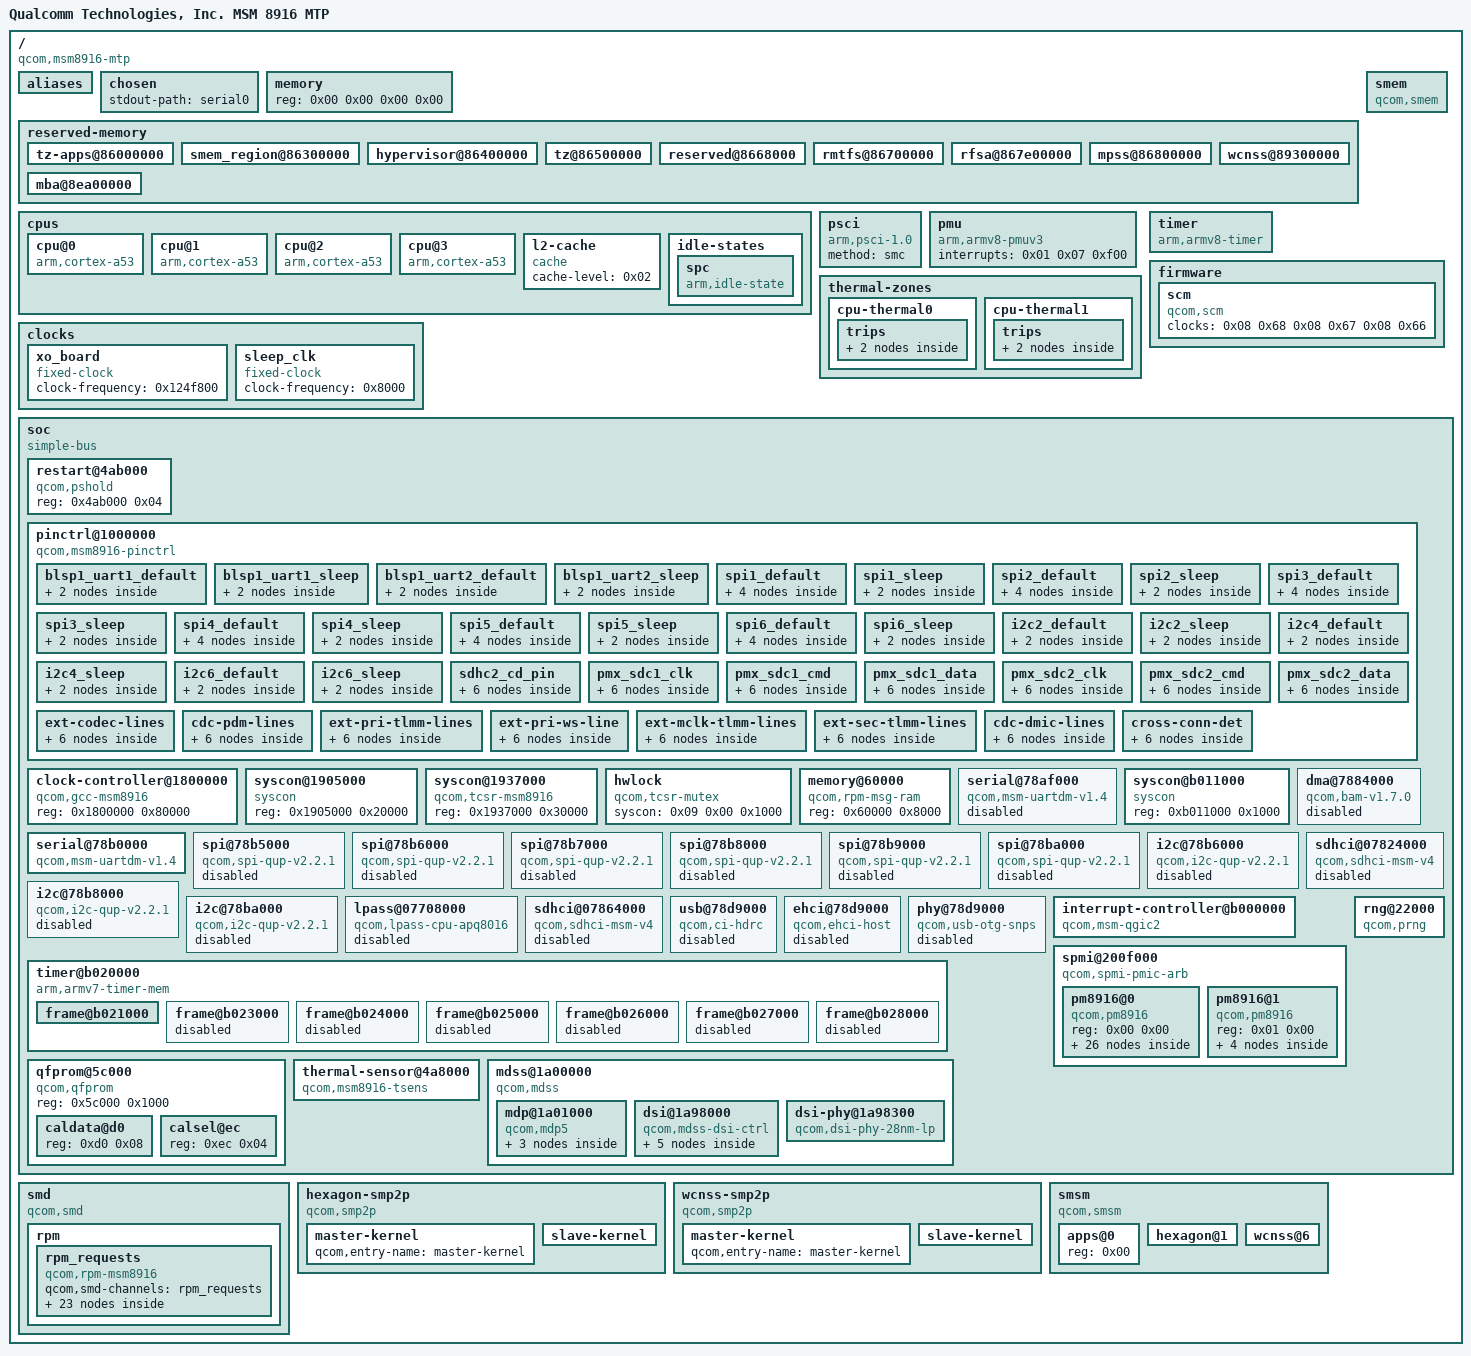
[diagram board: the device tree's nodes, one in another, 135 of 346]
/dts-v1/;

/ {
	model = "Qualcomm Technologies, Inc. MSM 8916 MTP";
	compatible = "qcom,msm8916-mtp\0qcom,msm8916-mtp/1\0qcom,msm8916\0qcom,mtp";
	interrupt-parent = <0x01>;
	#address-cells = <0x02>;
	#size-cells = <0x02>;

	aliases {
		sdhc1 = "/soc/sdhci@07824000";
		sdhc2 = "/soc/sdhci@07864000";
		serial0 = "/soc/serial@78b0000";
		usid0 = "/soc/spmi@200f000/pm8916@0";
	};

	chosen {
		stdout-path = "serial0";
	};

	memory {
		device_type = "memory";
		reg = <0x00 0x00 0x00 0x00>;
	};

	reserved-memory {
		#address-cells = <0x02>;
		#size-cells = <0x02>;
		ranges;

		tz-apps@86000000 {
			reg = <0x00 0x86000000 0x00 0x300000>;
			no-map;
		};

		smem_region@86300000 {
			reg = <0x00 0x86300000 0x00 0x100000>;
			no-map;
			phandle = <0x05>;
		};

		hypervisor@86400000 {
			reg = <0x00 0x86400000 0x00 0x100000>;
			no-map;
		};

		tz@86500000 {
			reg = <0x00 0x86500000 0x00 0x180000>;
			no-map;
		};

		reserved@8668000 {
			reg = <0x00 0x86680000 0x00 0x80000>;
			no-map;
		};

		rmtfs@86700000 {
			reg = <0x00 0x86700000 0x00 0xe0000>;
			no-map;
		};

		rfsa@867e00000 {
			reg = <0x00 0x867e0000 0x00 0x20000>;
			no-map;
		};

		mpss@86800000 {
			reg = <0x00 0x86800000 0x00 0x2b00000>;
			no-map;
		};

		wcnss@89300000 {
			reg = <0x00 0x89300000 0x00 0x600000>;
			no-map;
		};

		mba@8ea00000 {
			no-map;
			reg = <0x00 0x8ea00000 0x00 0x100000>;
			phandle = <0x2e>;
		};
	};

	cpus {
		#address-cells = <0x01>;
		#size-cells = <0x00>;

		cpu@0 {
			device_type = "cpu";
			compatible = "arm,cortex-a53\0arm,armv8";
			reg = <0x00>;
			next-level-cache = <0x02>;
			enable-method = "psci";
			cpu-idle-states = <0x03>;
			phandle = <0x2f>;
		};

		cpu@1 {
			device_type = "cpu";
			compatible = "arm,cortex-a53\0arm,armv8";
			reg = <0x01>;
			next-level-cache = <0x02>;
			enable-method = "psci";
			cpu-idle-states = <0x03>;
			phandle = <0x30>;
		};

		cpu@2 {
			device_type = "cpu";
			compatible = "arm,cortex-a53\0arm,armv8";
			reg = <0x02>;
			next-level-cache = <0x02>;
			enable-method = "psci";
			cpu-idle-states = <0x03>;
			phandle = <0x31>;
		};

		cpu@3 {
			device_type = "cpu";
			compatible = "arm,cortex-a53\0arm,armv8";
			reg = <0x03>;
			next-level-cache = <0x02>;
			enable-method = "psci";
			cpu-idle-states = <0x03>;
			phandle = <0x32>;
		};

		l2-cache {
			compatible = "cache";
			cache-level = <0x02>;
			phandle = <0x02>;
		};

		idle-states {

			spc {
				compatible = "arm,idle-state";
				arm,psci-suspend-param = <0x40000002>;
				entry-latency-us = <0x82>;
				exit-latency-us = <0x96>;
				min-residency-us = <0x7d0>;
				local-timer-stop;
				phandle = <0x03>;
			};
		};
	};

	psci {
		compatible = "arm,psci-1.0";
		method = "smc";
	};

	pmu {
		compatible = "arm,armv8-pmuv3";
		interrupts = <0x01 0x07 0xf00>;
	};

	thermal-zones {

		cpu-thermal0 {
			polling-delay-passive = <0xfa>;
			polling-delay = <0x3e8>;
			thermal-sensors = <0x04 0x04>;

			trips {

				trip0 {
					temperature = <0x124f8>;
					hysteresis = <0x7d0>;
					type = "passive";
					phandle = <0x33>;
				};

				trip1 {
					temperature = <0x1adb0>;
					hysteresis = <0x7d0>;
					type = "critical";
					phandle = <0x34>;
				};
			};
		};

		cpu-thermal1 {
			polling-delay-passive = <0xfa>;
			polling-delay = <0x3e8>;
			thermal-sensors = <0x04 0x03>;

			trips {

				trip0 {
					temperature = <0x124f8>;
					hysteresis = <0x7d0>;
					type = "passive";
					phandle = <0x35>;
				};

				trip1 {
					temperature = <0x1adb0>;
					hysteresis = <0x7d0>;
					type = "critical";
					phandle = <0x36>;
				};
			};
		};
	};

	timer {
		compatible = "arm,armv8-timer";
		interrupts = <0x01 0x02 0xf08 0x01 0x03 0xf08 0x01 0x04 0xf08 0x01 0x01 0xf08>;
	};

	clocks {

		xo_board {
			compatible = "fixed-clock";
			#clock-cells = <0x00>;
			clock-frequency = <0x124f800>;
			phandle = <0x37>;
		};

		sleep_clk {
			compatible = "fixed-clock";
			#clock-cells = <0x00>;
			clock-frequency = <0x8000>;
			phandle = <0x38>;
		};
	};

	smem {
		compatible = "qcom,smem";
		memory-region = <0x05>;
		qcom,rpm-msg-ram = <0x06>;
		hwlocks = <0x07 0x03>;
	};

	firmware {

		scm {
			compatible = "qcom,scm";
			clocks = <0x08 0x68 0x08 0x67 0x08 0x66>;
			clock-names = "core\0bus\0iface";
			#reset-cells = <0x01>;
			phandle = <0x39>;
		};
	};

	soc {
		#address-cells = <0x01>;
		#size-cells = <0x01>;
		ranges = <0x00 0x00 0x00 0xffffffff>;
		compatible = "simple-bus";
		phandle = <0x3a>;

		restart@4ab000 {
			compatible = "qcom,pshold";
			reg = <0x4ab000 0x04>;
		};

		pinctrl@1000000 {
			compatible = "qcom,msm8916-pinctrl";
			reg = <0x1000000 0x300000>;
			interrupts = <0x00 0xd0 0x04>;
			gpio-controller;
			#gpio-cells = <0x02>;
			interrupt-controller;
			#interrupt-cells = <0x02>;
			phandle = <0x3b>;

			blsp1_uart1_default {
				phandle = <0x3c>;

				pinmux {
					function = "blsp_uart1";
					pins = "gpio0\0gpio1\0gpio2\0gpio3";
				};

				pinconf {
					pins = "gpio0\0gpio1\0gpio2\0gpio3";
					drive-strength = <0x10>;
					bias-disable;
				};
			};

			blsp1_uart1_sleep {
				phandle = <0x3d>;

				pinmux {
					function = "gpio";
					pins = "gpio0\0gpio1\0gpio2\0gpio3";
				};

				pinconf {
					pins = "gpio0\0gpio1\0gpio2\0gpio3";
					drive-strength = <0x02>;
					bias-pull-down;
				};
			};

			blsp1_uart2_default {
				phandle = <0x0b>;

				pinmux {
					function = "blsp_uart2";
					pins = "gpio4\0gpio5";
				};

				pinconf {
					pins = "gpio4\0gpio5";
					drive-strength = <0x10>;
					bias-disable;
				};
			};

			blsp1_uart2_sleep {
				phandle = <0x0c>;

				pinmux {
					function = "gpio";
					pins = "gpio4\0gpio5";
				};

				pinconf {
					pins = "gpio4\0gpio5";
					drive-strength = <0x02>;
					bias-pull-down;
				};
			};

			spi1_default {
				phandle = <0x0d>;

				pinmux {
					function = "blsp_spi1";
					pins = "gpio0\0gpio1\0gpio3";
				};

				pinmux_cs {
					function = "gpio";
					pins = "gpio2";
				};

				pinconf {
					pins = "gpio0\0gpio1\0gpio3";
					drive-strength = <0x0c>;
					bias-disable;
				};

				pinconf_cs {
					pins = "gpio2";
					drive-strength = <0x10>;
					bias-disable;
					output-high;
				};
			};

			spi1_sleep {
				phandle = <0x0e>;

				pinmux {
					function = "gpio";
					pins = "gpio0\0gpio1\0gpio2\0gpio3";
				};

				pinconf {
					pins = "gpio0\0gpio1\0gpio2\0gpio3";
					drive-strength = <0x02>;
					bias-pull-down;
				};
			};

			spi2_default {
				phandle = <0x0f>;

				pinmux {
					function = "blsp_spi2";
					pins = "gpio4\0gpio5\0gpio7";
				};

				pinmux_cs {
					function = "gpio";
					pins = "gpio6";
				};

				pinconf {
					pins = "gpio4\0gpio5\0gpio7";
					drive-strength = <0x0c>;
					bias-disable;
				};

				pinconf_cs {
					pins = "gpio6";
					drive-strength = <0x10>;
					bias-disable;
					output-high;
				};
			};

			spi2_sleep {
				phandle = <0x10>;

				pinmux {
					function = "gpio";
					pins = "gpio4\0gpio5\0gpio6\0gpio7";
				};

				pinconf {
					pins = "gpio4\0gpio5\0gpio6\0gpio7";
					drive-strength = <0x02>;
					bias-pull-down;
				};
			};

			spi3_default {
				phandle = <0x11>;

				pinmux {
					function = "blsp_spi3";
					pins = "gpio8\0gpio9\0gpio11";
				};

				pinmux_cs {
					function = "gpio";
					pins = "gpio10";
				};

				pinconf {
					pins = "gpio8\0gpio9\0gpio11";
					drive-strength = <0x0c>;
					bias-disable;
				};

				pinconf_cs {
					pins = "gpio10";
					drive-strength = <0x10>;
					bias-disable;
					output-high;
				};
			};

			spi3_sleep {
				phandle = <0x12>;

				pinmux {
					function = "gpio";
					pins = "gpio8\0gpio9\0gpio10\0gpio11";
				};

				pinconf {
					pins = "gpio8\0gpio9\0gpio10\0gpio11";
					drive-strength = <0x02>;
					bias-pull-down;
				};
			};

			spi4_default {
				phandle = <0x13>;

				pinmux {
					function = "blsp_spi4";
					pins = "gpio12\0gpio13\0gpio15";
				};

				pinmux_cs {
					function = "gpio";
					pins = "gpio14";
				};

				pinconf {
					pins = "gpio12\0gpio13\0gpio15";
					drive-strength = <0x0c>;
					bias-disable;
				};

				pinconf_cs {
					pins = "gpio14";
					drive-strength = <0x10>;
					bias-disable;
					output-high;
				};
			};

			spi4_sleep {
				phandle = <0x14>;

				pinmux {
					function = "gpio";
					pins = "gpio12\0gpio13\0gpio14\0gpio15";
				};

				pinconf {
					pins = "gpio12\0gpio13\0gpio14\0gpio15";
					drive-strength = <0x02>;
					bias-pull-down;
				};
			};

			spi5_default {
				phandle = <0x15>;

				pinmux {
					function = "blsp_spi5";
					pins = "gpio16\0gpio17\0gpio19";
				};

				pinmux_cs {
					function = "gpio";
					pins = "gpio18";
				};

				pinconf {
					pins = "gpio16\0gpio17\0gpio19";
					drive-strength = <0x0c>;
					bias-disable;
				};

				pinconf_cs {
					pins = "gpio18";
					drive-strength = <0x10>;
					bias-disable;
					output-high;
				};
			};

			spi5_sleep {
				phandle = <0x16>;

				pinmux {
					function = "gpio";
					pins = "gpio16\0gpio17\0gpio18\0gpio19";
				};

				pinconf {
					pins = "gpio16\0gpio17\0gpio18\0gpio19";
					drive-strength = <0x02>;
					bias-pull-down;
				};
			};

			spi6_default {
				phandle = <0x17>;

				pinmux {
					function = "blsp_spi6";
					pins = "gpio20\0gpio21\0gpio23";
				};

				pinmux_cs {
					function = "gpio";
					pins = "gpio22";
				};

				pinconf {
					pins = "gpio20\0gpio21\0gpio23";
					drive-strength = <0x0c>;
					bias-disable;
				};

				pinconf_cs {
					pins = "gpio22";
					drive-strength = <0x10>;
					bias-disable;
					output-high;
				};
			};

			spi6_sleep {
				phandle = <0x18>;

				pinmux {
					function = "gpio";
					pins = "gpio20\0gpio21\0gpio22\0gpio23";
				};

				pinconf {
					pins = "gpio20\0gpio21\0gpio22\0gpio23";
					drive-strength = <0x02>;
					bias-pull-down;
				};
			};

			i2c2_default {
				phandle = <0x19>;

				pinmux {
					function = "blsp_i2c2";
					pins = "gpio6\0gpio7";
				};

				pinconf {
					pins = "gpio6\0gpio7";
					drive-strength = <0x10>;
					bias-disable = <0x00>;
				};
			};

			i2c2_sleep {
				phandle = <0x1a>;

				pinmux {
					function = "gpio";
					pins = "gpio6\0gpio7";
				};

				pinconf {
					pins = "gpio6\0gpio7";
					drive-strength = <0x02>;
					bias-disable = <0x00>;
				};
			};

			i2c4_default {
				phandle = <0x1b>;

				pinmux {
					function = "blsp_i2c4";
					pins = "gpio14\0gpio15";
				};

				pinconf {
					pins = "gpio14\0gpio15";
					drive-strength = <0x10>;
					bias-disable = <0x00>;
				};
			};

			i2c4_sleep {
				phandle = <0x1c>;

				pinmux {
					function = "gpio";
					pins = "gpio14\0gpio15";
				};

				pinconf {
					pins = "gpio14\0gpio15";
					drive-strength = <0x02>;
					bias-disable = <0x00>;
				};
			};

			i2c6_default {
				phandle = <0x1d>;

				pinmux {
					function = "blsp_i2c6";
					pins = "gpio22\0gpio23";
				};

				pinconf {
					pins = "gpio22\0gpio23";
					drive-strength = <0x10>;
					bias-disable = <0x00>;
				};
			};

			i2c6_sleep {
				phandle = <0x1e>;

				pinmux {
					function = "gpio";
					pins = "gpio22\0gpio23";
				};

				pinconf {
					pins = "gpio22\0gpio23";
					drive-strength = <0x02>;
					bias-disable = <0x00>;
				};
			};

			sdhc2_cd_pin {

				cd_on {
					phandle = <0x3e>;

					pinmux {
						function = "gpio";
						pins = "gpio38";
					};

					pinconf {
						pins = "gpio38";
						drive-strength = <0x02>;
						bias-pull-up;
					};
				};

				cd_off {
					phandle = <0x3f>;

					pinmux {
						function = "gpio";
						pins = "gpio38";
					};

					pinconf {
						pins = "gpio38";
						drive-strength = <0x02>;
						bias-disable;
					};
				};
			};

			pmx_sdc1_clk {

				clk_on {
					phandle = <0x40>;

					pinmux {
						pins = "sdc1_clk";
					};

					pinconf {
						pins = "sdc1_clk";
						bias-disable;
						drive-strength = <0x10>;
					};
				};

				clk_off {
					phandle = <0x41>;

					pinmux {
						pins = "sdc1_clk";
					};

					pinconf {
						pins = "sdc1_clk";
						bias-disable;
						drive-strength = <0x02>;
					};
				};
			};

			pmx_sdc1_cmd {

				cmd_on {
					phandle = <0x42>;

					pinmux {
						pins = "sdc1_cmd";
					};

					pinconf {
						pins = "sdc1_cmd";
						bias-pull-up;
						drive-strength = <0x0a>;
					};
				};

				cmd_off {
					phandle = <0x43>;

					pinmux {
						pins = "sdc1_cmd";
					};

					pinconf {
						pins = "sdc1_cmd";
						bias-pull-up;
						drive-strength = <0x02>;
					};
				};
			};

			pmx_sdc1_data {

				data_on {
					phandle = <0x44>;

					pinmux {
						pins = "sdc1_data";
					};

					pinconf {
						pins = "sdc1_data";
						bias-pull-up;
						drive-strength = <0x0a>;
					};
				};

				data_off {
					phandle = <0x45>;

					pinmux {
						pins = "sdc1_data";
					};

					pinconf {
						pins = "sdc1_data";
						bias-pull-up;
						drive-strength = <0x02>;
					};
				};
			};

			pmx_sdc2_clk {

				clk_on {
					phandle = <0x46>;

					pinmux {
						pins = "sdc2_clk";
					};

					pinconf {
						pins = "sdc2_clk";
						bias-disable;
						drive-strength = <0x10>;
					};
				};

				clk_off {
					phandle = <0x47>;

					pinmux {
						pins = "sdc2_clk";
					};

					pinconf {
						pins = "sdc2_clk";
						bias-disable;
						drive-strength = <0x02>;
					};
				};
			};

			pmx_sdc2_cmd {

				cmd_on {
					phandle = <0x48>;

					pinmux {
						pins = "sdc2_cmd";
					};

					pinconf {
						pins = "sdc2_cmd";
						bias-pull-up;
						drive-strength = <0x0a>;
					};
				};

				cmd_off {
					phandle = <0x49>;

					pinmux {
						pins = "sdc2_cmd";
					};

					pinconf {
						pins = "sdc2_cmd";
						bias-pull-up;
						drive-strength = <0x02>;
					};
				};
			};

			pmx_sdc2_data {

				data_on {
					phandle = <0x4a>;

					pinmux {
						pins = "sdc2_data";
					};

					pinconf {
						pins = "sdc2_data";
						bias-pull-up;
						drive-strength = <0x0a>;
					};
				};

				data_off {
					phandle = <0x4b>;

					pinmux {
						pins = "sdc2_data";
					};

					pinconf {
						pins = "sdc2_data";
						bias-pull-up;
						drive-strength = <0x02>;
					};
				};
			};

			ext-codec-lines {

				lines_on {
					phandle = <0x4c>;

					pinmux {
						function = "gpio";
						pins = "gpio67";
					};

					pinconf {
						pins = "gpio67";
						drive-strength = <0x08>;
						bias-disable;
						output-high;
					};
				};

				lines_off {
					phandle = <0x4d>;

					pinmux {
						function = "gpio";
						pins = "gpio67";
					};

					pinconf {
						pins = "gpio67";
						drive-strength = <0x02>;
						bias-disable;
					};
				};
			};

			cdc-pdm-lines {

				pdm_lines_on {
					phandle = <0x4e>;

					pinmux {
						function = "cdc_pdm0";
						pins = "gpio63\0gpio64\0gpio65\0gpio66\0gpio67\0gpio68";
					};

					pinconf {
						pins = "gpio63\0gpio64\0gpio65\0gpio66\0gpio67\0gpio68";
						drive-strength = <0x08>;
						bias-pull-none;
					};
				};

				pdm_lines_off {
					phandle = <0x4f>;

					pinmux {
						function = "cdc_pdm0";
						pins = "gpio63\0gpio64\0gpio65\0gpio66\0gpio67\0gpio68";
					};

					pinconf {
						pins = "gpio63\0gpio64\0gpio65\0gpio66\0gpio67\0gpio68";
						drive-strength = <0x02>;
						bias-disable;
					};
				};
			};

			ext-pri-tlmm-lines {

				ext_pa_on {
					phandle = <0x50>;

					pinmux {
						function = "pri_mi2s";
						pins = "gpio113\0gpio114\0gpio115\0gpio116";
					};

					pinconf {
						pins = "gpio113\0gpio114\0gpio115\0gpio116";
						drive-strength = <0x08>;
						bias-pull-none;
					};
				};

				ext_pa_off {
					phandle = <0x51>;

					pinmux {
						function = "pri_mi2s";
						pins = "gpio113\0gpio114\0gpio115\0gpio116";
					};

					pinconf {
						pins = "gpio113\0gpio114\0gpio115\0gpio116";
						drive-strength = <0x02>;
						bias-disable;
					};
				};
			};

			ext-pri-ws-line {

				ext_pa_on {
					phandle = <0x52>;

					pinmux {
						function = "pri_mi2s_ws";
						pins = "gpio110";
					};

					pinconf {
						pins = "gpio110";
						drive-strength = <0x08>;
						bias-pull-none;
					};
				};

				ext_pa_off {
					phandle = <0x53>;

					pinmux {
						function = "pri_mi2s_ws";
						pins = "gpio110";
					};

					pinconf {
						pins = "gpio110";
						drive-strength = <0x02>;
						bias-disable;
					};
				};
			};

			ext-mclk-tlmm-lines {

				mclk_lines_on {
					phandle = <0x54>;

					pinmux {
						function = "pri_mi2s";
						pins = "gpio116";
					};

					pinconf {
						pins = "gpio116";
						drive-strength = <0x08>;
						bias-pull-none;
					};
				};

				mclk_lines_off {
					phandle = <0x55>;

					pinmux {
						function = "pri_mi2s";
						pins = "gpio116";
					};

					pinconf {
						pins = "gpio116";
						drive-strength = <0x02>;
						bias-disable;
					};
				};
			};

			ext-sec-tlmm-lines {

				tlmm_lines_on {
					phandle = <0x56>;

					pinmux {
						function = "sec_mi2s";
						pins = "gpio112\0gpio117\0gpio118\0gpio119";
					};

					pinconf {
						pins = "gpio112\0gpio117\0gpio118\0gpio119";
						drive-strength = <0x08>;
						bias-pull-none;
					};
				};

				tlmm_lines_off {
					phandle = <0x57>;

					pinmux {
						function = "sec_mi2s";
						pins = "gpio112\0gpio117\0gpio118\0gpio119";
					};

					pinconf {
						pins = "gpio112\0gpio117\0gpio118\0gpio119";
						drive-strength = <0x02>;
						bias-disable;
					};
				};
			};

			cdc-dmic-lines {

				dmic_lines_on {
					phandle = <0x58>;

					pinmux_dmic0_clk {
						function = "dmic0_clk";
						pins = "gpio0";
					};

					pinmux_dmic0_data {
						function = "dmic0_data";
						pins = "gpio1";
					};

					pinconf {
						pins = "gpio0\0gpio1";
						drive-strength = <0x08>;
					};
				};

				dmic_lines_off {
					phandle = <0x59>;

					pinconf {
						pins = "gpio0\0gpio1";
						drive-strength = <0x02>;
						bias-disable;
					};
				};
			};

			cross-conn-det {

				lines_on {
					phandle = <0x5a>;

					pinmux {
						function = "gpio";
						pins = "gpio120";
					};

					pinconf {
						pins = "gpio120";
						drive-strength = <0x08>;
						output-low;
						bias-pull-down;
					};
				};

				lines_off {
					phandle = <0x5b>;

					pinmux {
						function = "gpio";
						pins = "gpio120";
					};

					pinconf {
						pins = "gpio120";
						drive-strength = <0x02>;
						bias-disable;
					};
				};
			};
		};

		clock-controller@1800000 {
			compatible = "qcom,gcc-msm8916";
			#clock-cells = <0x01>;
			#reset-cells = <0x01>;
			#power-domain-cells = <0x01>;
			reg = <0x1800000 0x80000>;
			phandle = <0x08>;
		};

		syscon@1905000 {
			compatible = "syscon";
			reg = <0x1905000 0x20000>;
			phandle = <0x09>;
		};

		syscon@1937000 {
			compatible = "qcom,tcsr-msm8916\0syscon";
			reg = <0x1937000 0x30000>;
			phandle = <0x5c>;
		};

		hwlock {
			compatible = "qcom,tcsr-mutex";
			syscon = <0x09 0x00 0x1000>;
			#hwlock-cells = <0x01>;
			phandle = <0x07>;
		};

		memory@60000 {
			compatible = "qcom,rpm-msg-ram";
			reg = <0x60000 0x8000>;
			phandle = <0x06>;
		};

		serial@78af000 {
			compatible = "qcom,msm-uartdm-v1.4\0qcom,msm-uartdm";
			reg = <0x78af000 0x200>;
			interrupts = <0x00 0x6b 0x04>;
			clocks = <0x08 0x44 0x08 0x36>;
			clock-names = "core\0iface";
			dmas = <0x0a 0x01 0x0a 0x00>;
			dma-names = "rx\0tx";
			status = "disabled";
			phandle = <0x5d>;
		};

		syscon@b011000 {
			compatible = "syscon";
			reg = <0xb011000 0x1000>;
			phandle = <0x2d>;
		};

		serial@78b0000 {
			compatible = "qcom,msm-uartdm-v1.4\0qcom,msm-uartdm";
			reg = <0x78b0000 0x200>;
			interrupts = <0x00 0x6c 0x04>;
			clocks = <0x08 0x45 0x08 0x36>;
			clock-names = "core\0iface";
			dmas = <0x0a 0x03 0x0a 0x02>;
			dma-names = "rx\0tx";
			status = "okay";
			pinctrl-names = "default\0sleep";
			pinctrl-0 = <0x0b>;
			pinctrl-1 = <0x0c>;
			phandle = <0x5e>;
		};

		dma@7884000 {
			compatible = "qcom,bam-v1.7.0";
			reg = <0x7884000 0x23000>;
			interrupts = <0x00 0xee 0x04>;
			clocks = <0x08 0x36>;
			clock-names = "bam_clk";
			#dma-cells = <0x01>;
			qcom,ee = <0x00>;
			status = "disabled";
			phandle = <0x0a>;
		};

		spi@78b5000 {
			compatible = "qcom,spi-qup-v2.2.1";
			reg = <0x78b5000 0x600>;
			interrupts = <0x00 0x5f 0x04>;
			clocks = <0x08 0x39 0x08 0x36>;
			clock-names = "core\0iface";
			dmas = <0x0a 0x05 0x0a 0x04>;
			dma-names = "rx\0tx";
			pinctrl-names = "default\0sleep";
			pinctrl-0 = <0x0d>;
			pinctrl-1 = <0x0e>;
			#address-cells = <0x01>;
			#size-cells = <0x00>;
			status = "disabled";
			phandle = <0x5f>;
		};

		spi@78b6000 {
			compatible = "qcom,spi-qup-v2.2.1";
			reg = <0x78b6000 0x600>;
			interrupts = <0x00 0x60 0x04>;
			clocks = <0x08 0x3b 0x08 0x36>;
			clock-names = "core\0iface";
			dmas = <0x0a 0x07 0x0a 0x06>;
			dma-names = "rx\0tx";
			pinctrl-names = "default\0sleep";
			pinctrl-0 = <0x0f>;
			pinctrl-1 = <0x10>;
			#address-cells = <0x01>;
			#size-cells = <0x00>;
			status = "disabled";
			phandle = <0x60>;
		};

		spi@78b7000 {
			compatible = "qcom,spi-qup-v2.2.1";
			reg = <0x78b7000 0x600>;
			interrupts = <0x00 0x61 0x04>;
			clocks = <0x08 0x3d 0x08 0x36>;
			clock-names = "core\0iface";
			dmas = <0x0a 0x09 0x0a 0x08>;
			dma-names = "rx\0tx";
			pinctrl-names = "default\0sleep";
			pinctrl-0 = <0x11>;
			pinctrl-1 = <0x12>;
			#address-cells = <0x01>;
			#size-cells = <0x00>;
			status = "disabled";
			phandle = <0x61>;
		};

		spi@78b8000 {
			compatible = "qcom,spi-qup-v2.2.1";
			reg = <0x78b8000 0x600>;
			interrupts = <0x00 0x62 0x04>;
			clocks = <0x08 0x3f 0x08 0x36>;
			clock-names = "core\0iface";
			dmas = <0x0a 0x0b 0x0a 0x0a>;
			dma-names = "rx\0tx";
			pinctrl-names = "default\0sleep";
			pinctrl-0 = <0x13>;
			pinctrl-1 = <0x14>;
			#address-cells = <0x01>;
			#size-cells = <0x00>;
			status = "disabled";
			phandle = <0x62>;
		};

		spi@78b9000 {
			compatible = "qcom,spi-qup-v2.2.1";
			reg = <0x78b9000 0x600>;
			interrupts = <0x00 0x63 0x04>;
			clocks = <0x08 0x41 0x08 0x36>;
			clock-names = "core\0iface";
			dmas = <0x0a 0x0d 0x0a 0x0c>;
			dma-names = "rx\0tx";
			pinctrl-names = "default\0sleep";
			pinctrl-0 = <0x15>;
			pinctrl-1 = <0x16>;
			#address-cells = <0x01>;
			#size-cells = <0x00>;
			status = "disabled";
			phandle = <0x63>;
		};

		spi@78ba000 {
			compatible = "qcom,spi-qup-v2.2.1";
			reg = <0x78ba000 0x600>;
			interrupts = <0x00 0x64 0x04>;
			clocks = <0x08 0x43 0x08 0x36>;
			clock-names = "core\0iface";
			dmas = <0x0a 0x0f 0x0a 0x0e>;
			dma-names = "rx\0tx";
			pinctrl-names = "default\0sleep";
			pinctrl-0 = <0x17>;
			pinctrl-1 = <0x18>;
			#address-cells = <0x01>;
			#size-cells = <0x00>;
			status = "disabled";
			phandle = <0x64>;
		};

		i2c@78b6000 {
			compatible = "qcom,i2c-qup-v2.2.1";
			reg = <0x78b6000 0x1000>;
			interrupts = <0x00 0x60 0x00>;
			clocks = <0x08 0x36 0x08 0x3a>;
			clock-names = "iface\0core";
			pinctrl-names = "default\0sleep";
			pinctrl-0 = <0x19>;
			pinctrl-1 = <0x1a>;
			#address-cells = <0x01>;
			#size-cells = <0x00>;
			status = "disabled";
			phandle = <0x65>;
		};

		i2c@78b8000 {
			compatible = "qcom,i2c-qup-v2.2.1";
			reg = <0x78b8000 0x1000>;
			interrupts = <0x00 0x62 0x00>;
			clocks = <0x08 0x36 0x08 0x3e>;
			clock-names = "iface\0core";
			pinctrl-names = "default\0sleep";
			pinctrl-0 = <0x1b>;
			pinctrl-1 = <0x1c>;
			#address-cells = <0x01>;
			#size-cells = <0x00>;
			status = "disabled";
			phandle = <0x66>;
		};

		i2c@78ba000 {
			compatible = "qcom,i2c-qup-v2.2.1";
			reg = <0x78ba000 0x1000>;
			interrupts = <0x00 0x64 0x00>;
			clocks = <0x08 0x36 0x08 0x42>;
			clock-names = "iface\0core";
			pinctrl-names = "default\0sleep";
			pinctrl-0 = <0x1d>;
			pinctrl-1 = <0x1e>;
			#address-cells = <0x01>;
			#size-cells = <0x00>;
			status = "disabled";
			phandle = <0x67>;
		};

		lpass@07708000 {
			status = "disabled";
			compatible = "qcom,lpass-cpu-apq8016";
			clocks = <0x08 0x9a 0x08 0x96 0x08 0x97 0x08 0x9c 0x08 0x9d 0x08 0x9d 0x08 0x9e>;
			clock-names = "ahbix-clk\0pcnoc-mport-clk\0pcnoc-sway-clk\0mi2s-bit-clk0\0mi2s-bit-clk1\0mi2s-bit-clk2\0mi2s-bit-clk3";
			#sound-dai-cells = <0x01>;
			interrupts = <0x00 0xa0 0x00>;
			interrupt-names = "lpass-irq-lpaif";
			reg = <0x7708000 0x10000>;
			reg-names = "lpass-lpaif";
			phandle = <0x68>;
		};

		sdhci@07824000 {
			compatible = "qcom,sdhci-msm-v4";
			reg = <0x7824900 0x11c 0x7824000 0x800>;
			reg-names = "hc_mem\0core_mem";
			interrupts = <0x00 0x7b 0x00 0x00 0x8a 0x00>;
			interrupt-names = "hc_irq\0pwr_irq";
			clocks = <0x08 0x7b 0x08 0x7a>;
			clock-names = "core\0iface";
			bus-width = <0x08>;
			non-removable;
			status = "disabled";
			phandle = <0x69>;
		};

		sdhci@07864000 {
			compatible = "qcom,sdhci-msm-v4";
			reg = <0x7864900 0x11c 0x7864000 0x800>;
			reg-names = "hc_mem\0core_mem";
			interrupts = <0x00 0x7d 0x00 0x00 0xdd 0x00>;
			interrupt-names = "hc_irq\0pwr_irq";
			clocks = <0x08 0x7d 0x08 0x7c>;
			clock-names = "core\0iface";
			bus-width = <0x04>;
			status = "disabled";
			phandle = <0x6a>;
		};

		usb@78d9000 {
			compatible = "qcom,ci-hdrc";
			reg = <0x78d9000 0x400>;
			dr_mode = "peripheral";
			interrupts = <0x00 0x86 0x04>;
			usb-phy = <0x1f>;
			status = "disabled";
			phandle = <0x6b>;
		};

		ehci@78d9000 {
			compatible = "qcom,ehci-host";
			reg = <0x78d9000 0x400>;
			interrupts = <0x00 0x86 0x04>;
			usb-phy = <0x1f>;
			status = "disabled";
			phandle = <0x6c>;
		};

		phy@78d9000 {
			compatible = "qcom,usb-otg-snps";
			reg = <0x78d9000 0x400>;
			interrupts = <0x00 0x86 0x04 0x00 0x8c 0x04>;
			qcom,vdd-levels = <0x7a120 0xf4240 0x142440>;
			qcom,phy-init-sequence = <0x44 0x6b 0x24 0x13>;
			dr_mode = "peripheral";
			qcom,otg-control = <0x02>;
			qcom,manual-pullup;
			clocks = <0x08 0x85 0x08 0x86 0x08 0x84>;
			clock-names = "iface\0core\0sleep";
			resets = <0x08 0x23 0x08 0x22>;
			reset-names = "phy\0link";
			status = "disabled";
			phandle = <0x1f>;
		};

		interrupt-controller@b000000 {
			compatible = "qcom,msm-qgic2";
			interrupt-controller;
			#interrupt-cells = <0x03>;
			reg = <0xb000000 0x1000 0xb002000 0x1000>;
			phandle = <0x01>;
		};

		timer@b020000 {
			#address-cells = <0x01>;
			#size-cells = <0x01>;
			ranges;
			compatible = "arm,armv7-timer-mem";
			reg = <0xb020000 0x1000>;
			clock-frequency = <0x124f800>;

			frame@b021000 {
				frame-number = <0x00>;
				interrupts = <0x00 0x08 0x04 0x00 0x07 0x04>;
				reg = <0xb021000 0x1000 0xb022000 0x1000>;
			};

			frame@b023000 {
				frame-number = <0x01>;
				interrupts = <0x00 0x09 0x04>;
				reg = <0xb023000 0x1000>;
				status = "disabled";
			};

			frame@b024000 {
				frame-number = <0x02>;
				interrupts = <0x00 0x0a 0x04>;
				reg = <0xb024000 0x1000>;
				status = "disabled";
			};

			frame@b025000 {
				frame-number = <0x03>;
				interrupts = <0x00 0x0b 0x04>;
				reg = <0xb025000 0x1000>;
				status = "disabled";
			};

			frame@b026000 {
				frame-number = <0x04>;
				interrupts = <0x00 0x0c 0x04>;
				reg = <0xb026000 0x1000>;
				status = "disabled";
			};

			frame@b027000 {
				frame-number = <0x05>;
				interrupts = <0x00 0x0d 0x04>;
				reg = <0xb027000 0x1000>;
				status = "disabled";
			};

			frame@b028000 {
				frame-number = <0x06>;
				interrupts = <0x00 0x0e 0x04>;
				reg = <0xb028000 0x1000>;
				status = "disabled";
			};
		};

		spmi@200f000 {
			compatible = "qcom,spmi-pmic-arb";
			reg = <0x200f000 0x1000 0x2400000 0x400000 0x2c00000 0x400000 0x3800000 0x200000 0x200a000 0x2100>;
			reg-names = "core\0chnls\0obsrvr\0intr\0cnfg";
			interrupt-names = "periph_irq";
			interrupts = <0x00 0xbe 0x04>;
			qcom,ee = <0x00>;
			qcom,channel = <0x00>;
			#address-cells = <0x02>;
			#size-cells = <0x00>;
			interrupt-controller;
			#interrupt-cells = <0x04>;
			phandle = <0x23>;

			pm8916@0 {
				compatible = "qcom,pm8916\0qcom,spmi-pmic";
				reg = <0x00 0x00>;
				#address-cells = <0x01>;
				#size-cells = <0x01>;
				phandle = <0x6d>;

				qcom,revid@100 {
					compatible = "qcom,qpnp-revid";
					reg = <0x100 0x100>;
					phandle = <0x20>;
				};

				qcom,power-on@800 {
					compatible = "qcom,qpnp-power-on";
					reg = <0x800 0x100>;
					interrupts = <0x00 0x08 0x00 0x00 0x00 0x08 0x01 0x00>;
					interrupt-names = "kpdpwr\0resin";
					qcom,pon-dbc-delay = <0x3d09>;
					qcom,system-reset;
					qcom,clear-warm-reset;
					qcom,store-hard-reset-reason;
					phandle = <0x6e>;

					qcom,pon_1 {
						qcom,pon-type = <0x00>;
						qcom,support-reset = <0x01>;
						qcom,pull-up = <0x01>;
						qcom,s1-timer = <0x2810>;
						qcom,s2-timer = <0x7d0>;
						qcom,s2-type = <0x01>;
						linux,code = <0x74>;
					};

					qcom,pon_2 {
						qcom,pon-type = <0x01>;
						qcom,pull-up = <0x01>;
						linux,code = <0x72>;
					};
				};

				pinctrl@c000 {
					compatible = "qcom,pm8916-gpio";
					reg = <0xc000 0x400>;
					gpio-controller;
					#gpio-cells = <0x02>;
					interrupts = <0x00 0xc0 0x00 0x00 0x00 0xc1 0x00 0x00 0x00 0xc2 0x00 0x00 0x00 0xc3 0x00 0x00>;
					interrupt-names = "pm8916_gpio1\0pm8916_gpio2\0pm8916_gpio3\0pm8916_gpio4";
					phandle = <0x6f>;
				};

				mpps@a000 {
					compatible = "qcom,pm8916-mpp";
					reg = <0xa000 0x400>;
					gpio-controller;
					#gpio-cells = <0x02>;
					interrupts = <0x00 0xa0 0x00 0x00 0x00 0xa1 0x00 0x00 0x00 0xa2 0x00 0x00 0x00 0xa3 0x00 0x00>;
					interrupt-names = "pm8916_mpp1\0pm8916_mpp2\0pm8916_mpp3\0pm8916_mpp4";
					phandle = <0x70>;
				};

				qcom,coincell@2800 {
					compatible = "qcom,qpnp-coincell";
					reg = <0x2800 0x100>;
					phandle = <0x71>;
				};

				qcom,pm8916_rtc {
					compatible = "qcom,qpnp-rtc";
					#address-cells = <0x01>;
					#size-cells = <0x01>;
					qcom,qpnp-rtc-write = <0x00>;
					qcom,qpnp-rtc-alarm-pwrup = <0x00>;
					phandle = <0x72>;

					qcom,pm8916_rtc_rw@6000 {
						reg = <0x6000 0x100>;
					};

					qcom,pm8916_rtc_alarm@6100 {
						reg = <0x6100 0x100>;
						interrupts = <0x00 0x61 0x01 0x00>;
					};
				};

				vadc@3100 {
					compatible = "qcom,qpnp-vadc";
					reg = <0x3100 0x100>;
					#address-cells = <0x01>;
					#size-cells = <0x00>;
					interrupts = <0x00 0x31 0x00 0x01>;
					interrupt-names = "eoc-int-en-set";
					qcom,adc-bit-resolution = <0x0f>;
					qcom,adc-vdd-reference = <0x708>;
					qcom,vadc-poll-eoc;
					qcom,pmic-revid = <0x20>;
					#thermal-sensor-cells = <0x01>;
					phandle = <0x21>;

					chan@8 {
						label = "die_temp";
						reg = <0x08>;
						qcom,decimation = <0x00>;
						qcom,pre-div-channel-scaling = <0x00>;
						qcom,calibration-type = "absolute";
						qcom,scale-function = <0x03>;
						qcom,hw-settle-time = <0x00>;
						qcom,fast-avg-setup = <0x00>;
					};

					chan@9 {
						label = "ref_625mv";
						reg = <0x09>;
						qcom,decimation = <0x00>;
						qcom,pre-div-channel-scaling = <0x00>;
						qcom,calibration-type = "absolute";
						qcom,scale-function = <0x00>;
						qcom,hw-settle-time = <0x00>;
						qcom,fast-avg-setup = <0x00>;
					};

					chan@a {
						label = "ref_1250v";
						reg = <0x0a>;
						qcom,decimation = <0x00>;
						qcom,pre-div-channel-scaling = <0x00>;
						qcom,calibration-type = "absolute";
						qcom,scale-function = <0x00>;
						qcom,hw-settle-time = <0x00>;
						qcom,fast-avg-setup = <0x00>;
					};
				};

				qcom,temp-alarm@2400 {
					compatible = "qcom,qpnp-temp-alarm";
					reg = <0x2400 0x100>;
					interrupts = <0x00 0x24 0x00 0x01>;
					label = "pm8916_tz";
					qcom,channel-num = <0x08>;
					qcom,threshold-set = <0x00>;
					qcom,temp_alarm-vadc = <0x21>;
					#thermal-sensor-cells = <0x00>;
					phandle = <0x73>;
				};

				vadc@3400 {
					compatible = "qcom,qpnp-adc-tm";
					reg = <0x3400 0x100>;
					#address-cells = <0x01>;
					#size-cells = <0x00>;
					interrupts = <0x00 0x34 0x00 0x01 0x00 0x34 0x03 0x01 0x00 0x34 0x04 0x01>;
					interrupt-names = "eoc-int-en-set\0high-thr-en-set\0low-thr-en-set";
					qcom,adc-bit-resolution = <0x0f>;
					qcom,adc-vdd-reference = <0x708>;
					qcom,adc_tm-vadc = <0x21>;
					qcom,pmic-revid = <0x20>;
					phandle = <0x22>;
				};

				qcom,charger {
					compatible = "qcom,qpnp-linear-charger";
					#address-cells = <0x01>;
					#size-cells = <0x01>;
					qcom,vddmax-mv = <0x1068>;
					qcom,vddsafe-mv = <0x1068>;
					qcom,vinmin-mv = <0x10d4>;
					qcom,ibatsafe-ma = <0x5a0>;
					qcom,thermal-mitigation = <0x5a0 0x2d0 0x276 0x00>;
					qcom,cool-bat-decidegc = <0x64>;
					qcom,warm-bat-decidegc = <0x1c2>;
					qcom,cool-bat-mv = <0x1004>;
					qcom,warm-bat-mv = <0x1004>;
					qcom,ibatmax-warm-ma = <0x168>;
					qcom,ibatmax-cool-ma = <0x168>;
					qcom,batt-hot-percentage = <0x19>;
					qcom,batt-cold-percentage = <0x50>;
					qcom,tchg-mins = <0xe8>;
					qcom,resume-soc = <0x63>;
					qcom,chg-vadc = <0x21>;
					qcom,chg-adc_tm = <0x22>;
					status = "disabled";
					phandle = <0x74>;

					qcom,chgr@1000 {
						reg = <0x1000 0x100>;
						interrupts = <0x00 0x10 0x07 0x01 0x00 0x10 0x06 0x01 0x00 0x10 0x05 0x03 0x00 0x10 0x00 0x02>;
						interrupt-names = "chg-done\0chg-failed\0fast-chg-on\0vbat-det-lo";
					};

					qcom,bat-if@1200 {
						reg = <0x1200 0x100>;
						interrupts = <0x00 0x12 0x01 0x03 0x00 0x12 0x00 0x03>;
						interrupt-names = "bat-temp-ok\0batt-pres";
					};

					qcom,usb-chgpth@1300 {
						reg = <0x1300 0x100>;
						interrupts = <0x00 0x13 0x04 0x03 0x00 0x13 0x02 0x01 0x00 0x13 0x01 0x03>;
						interrupt-names = "usb-over-temp\0chg-gone\0usbin-valid";
					};

					qcom,chg-misc@1600 {
						reg = <0x1600 0x100>;
					};
				};

				qcom,vmbms {
					compatible = "qcom,qpnp-vm-bms";
					#address-cells = <0x01>;
					#size-cells = <0x01>;
					status = "disabled";
					qcom,v-cutoff-uv = <0x33e140>;
					qcom,max-voltage-uv = <0x401640>;
					qcom,r-conn-mohm = <0x00>;
					qcom,shutdown-soc-valid-limit = <0x64>;
					qcom,low-soc-calculate-soc-threshold = <0x0f>;
					qcom,low-voltage-calculate-soc-ms = <0x3e8>;
					qcom,low-soc-calculate-soc-ms = <0x1388>;
					qcom,calculate-soc-ms = <0x4e20>;
					qcom,volatge-soc-timeout-ms = <0xea60>;
					qcom,low-voltage-threshold = <0x34a490>;
					qcom,s3-ocv-tolerence-uv = <0x4b0>;
					qcom,s2-fifo-length = <0x05>;
					qcom,low-soc-fifo-length = <0x02>;
					qcom,bms-vadc = <0x21>;
					qcom,bms-adc_tm = <0x22>;
					qcom,pmic-revid = <0x20>;
					qcom,force-s3-on-suspend;
					qcom,force-s2-in-charging;
					qcom,report-charger-eoc;
					phandle = <0x75>;

					qcom,batt-pres-status@1208 {
						reg = <0x1208 0x01>;
					};

					qcom,qpnp-chg-pres@1008 {
						reg = <0x1008 0x01>;
					};

					qcom,vm-bms@4000 {
						reg = <0x4000 0x100>;
						interrupts = <0x00 0x40 0x00 0x00 0x00 0x40 0x01 0x00 0x00 0x40 0x02 0x00 0x00 0x40 0x03 0x00 0x00 0x40 0x04 0x00 0x00 0x40 0x05 0x00>;
						interrupt-names = "leave_cv\0enter_cv\0good_ocv\0ocv_thr\0fifo_update_done\0fsm_state_change";
					};
				};

				qcom,leds@a100 {
					compatible = "qcom,leds-qpnp";
					reg = <0xa100 0x100>;
					label = "mpp";
					phandle = <0x76>;
				};
			};

			pm8916@1 {
				compatible = "qcom,pm8916\0qcom,spmi-pmic";
				reg = <0x01 0x00>;
				#address-cells = <0x01>;
				#size-cells = <0x01>;
				phandle = <0x77>;

				qcom,pwms@bc00 {
					compatible = "qcom,pwm-lpg";
					reg = <0xbc00 0x100>;
					reg-names = "lpg-base";
					#pwm-cells = <0x02>;
					phandle = <0x78>;
				};

				qcom,vibrator@c000 {
					compatible = "qcom,qpnp-vibrator";
					reg = <0xc000 0x100>;
					label = "vibrator";
					status = "disabled";
					phandle = <0x79>;
				};

				msm8x16_wcd_codec@f000 {
					compatible = "qcom,msm8x16_wcd_codec";
					reg = <0xf000 0x100>;
					interrupt-parent = <0x23>;
					interrupts = <0x01 0xf0 0x00 0x00 0x01 0xf0 0x01 0x00 0x01 0xf0 0x02 0x00 0x01 0xf0 0x03 0x00 0x01 0xf0 0x04 0x00 0x01 0xf0 0x05 0x00 0x01 0xf0 0x06 0x00 0x01 0xf0 0x07 0x00>;
					interrupt-names = "spk_cnp_int\0spk_clip_int\0spk_ocp_int\0ins_rem_det1\0but_rel_det\0but_press_det\0ins_rem_det\0mbhc_int";
					cdc-vdda-cp-supply = <0x24>;
					qcom,cdc-vdda-cp-voltage = <0x1b7740 0x2191c0>;
					qcom,cdc-vdda-cp-current = <0xbbfd0>;
					cdc-vdda-h-supply = <0x25>;
					qcom,cdc-vdda-h-voltage = <0x1b7740 0x1b7740>;
					qcom,cdc-vdda-h-current = <0x4e20>;
					cdc-vdd-px-supply = <0x24>;
					qcom,cdc-vdd-px-voltage = <0x1b7740 0x2191c0>;
					qcom,cdc-vdd-px-current = <0xbbfd0>;
					cdc-vdd-pa-supply = <0x25>;
					qcom,cdc-vdd-pa-voltage = <0x1b7740 0x1b7740>;
					qcom,cdc-vdd-pa-current = <0x1388>;
					cdc-vdd-mic-bias-supply = <0x26>;
					qcom,cdc-vdd-mic-bias-voltage = <0x2eebb8 0x2eebb8>;
					qcom,cdc-vdd-mic-bias-current = <0x61a8>;
					qcom,cdc-mclk-clk-rate = <0x927c00>;
					qcom,cdc-static-supplies = "cdc-vdda-h\0cdc-vdd-px\0cdc-vdd-pa\0cdc-vdda-cp";
					qcom,cdc-on-demand-supplies = "cdc-vdd-mic-bias";
					qcom,subsys-name = "modem";
					phandle = <0x7a>;
				};

				msm8x16_wcd_codec@f100 {
					compatible = "qcom,msm8x16_wcd_codec";
					reg = <0xf100 0x100>;
					interrupt-parent = <0x23>;
					interrupts = <0x01 0xf1 0x00 0x00 0x01 0xf1 0x01 0x00 0x01 0xf1 0x02 0x00 0x01 0xf1 0x03 0x00 0x01 0xf1 0x04 0x00 0x01 0xf1 0x05 0x00>;
					interrupt-names = "ear_ocp_int\0hphr_ocp_int\0hphl_ocp_det\0ear_cnp_int\0hphr_cnp_int\0hphl_cnp_int";
					phandle = <0x7b>;
				};
			};
		};

		rng@22000 {
			compatible = "qcom,prng";
			reg = <0x22000 0x200>;
			clocks = <0x08 0x79>;
			clock-names = "core";
		};

		qfprom@5c000 {
			compatible = "qcom,qfprom";
			reg = <0x5c000 0x1000>;
			#address-cells = <0x01>;
			#size-cells = <0x01>;
			phandle = <0x7c>;

			caldata@d0 {
				reg = <0xd0 0x08>;
				phandle = <0x27>;
			};

			calsel@ec {
				reg = <0xec 0x04>;
				phandle = <0x28>;
			};
		};

		thermal-sensor@4a8000 {
			compatible = "qcom,msm8916-tsens";
			reg = <0x4a8000 0x2000>;
			nvmem-cells = <0x27 0x28>;
			nvmem-cell-names = "calib\0calib_sel";
			#thermal-sensor-cells = <0x01>;
			phandle = <0x04>;
		};

		mdss@1a00000 {
			compatible = "qcom,mdss";
			reg = <0x1a00000 0x1000 0x1ac8000 0x3000>;
			reg-names = "mdss_phys\0vbif_phys";
			power-domains = <0x08 0x02>;
			clocks = <0x08 0x6d 0x08 0x6e 0x08 0x73>;
			clock-names = "iface_clk\0bus_clk\0vsync_clk";
			interrupts = <0x00 0x48 0x00>;
			interrupt-controller;
			#interrupt-cells = <0x01>;
			#address-cells = <0x01>;
			#size-cells = <0x01>;
			ranges;
			phandle = <0x29>;

			mdp@1a01000 {
				compatible = "qcom,mdp5";
				reg = <0x1a01000 0x90000>;
				reg-names = "mdp_phys";
				interrupt-parent = <0x29>;
				interrupts = <0x00 0x00>;
				clocks = <0x08 0x6d 0x08 0x6e 0x08 0x71 0x08 0x73>;
				clock-names = "iface_clk\0bus_clk\0core_clk\0vsync_clk";
				phandle = <0x7d>;

				ports {
					#address-cells = <0x01>;
					#size-cells = <0x00>;

					port@0 {
						reg = <0x00>;

						endpoint {
							remote-endpoint = <0x2a>;
							phandle = <0x2c>;
						};
					};
				};
			};

			dsi@1a98000 {
				compatible = "qcom,mdss-dsi-ctrl";
				reg = <0x1a98000 0x25c>;
				reg-names = "dsi_ctrl";
				interrupt-parent = <0x29>;
				interrupts = <0x04 0x00>;
				assigned-clocks = <0x08 0x2b 0x08 0x2e>;
				assigned-clock-parents = <0x2b 0x00 0x2b 0x01>;
				clocks = <0x08 0x71 0x08 0x6d 0x08 0x6e 0x08 0x6f 0x08 0x72 0x08 0x70>;
				clock-names = "mdp_core_clk\0iface_clk\0bus_clk\0byte_clk\0pixel_clk\0core_clk";
				phys = <0x2b>;
				phy-names = "dsi-phy";
				phandle = <0x7e>;

				ports {
					#address-cells = <0x01>;
					#size-cells = <0x00>;

					port@0 {
						reg = <0x00>;

						endpoint {
							remote-endpoint = <0x2c>;
							phandle = <0x2a>;
						};
					};

					port@1 {
						reg = <0x01>;

						endpoint {
							phandle = <0x7f>;
						};
					};
				};
			};

			dsi-phy@1a98300 {
				compatible = "qcom,dsi-phy-28nm-lp";
				reg = <0x1a98300 0xd4 0x1a98500 0x280 0x1a98780 0x30>;
				reg-names = "dsi_pll\0dsi_phy\0dsi_phy_regulator";
				#clock-cells = <0x01>;
				#phy-cells = <0x00>;
				clocks = <0x08 0x6d>;
				clock-names = "iface_clk";
				phandle = <0x2b>;
			};
		};
	};

	smd {
		compatible = "qcom,smd";

		rpm {
			interrupts = <0x00 0xa8 0x01>;
			qcom,ipc = <0x2d 0x08 0x00>;
			qcom,smd-edge = <0x0f>;

			rpm_requests {
				compatible = "qcom,rpm-msm8916";
				qcom,smd-channels = "rpm_requests";

				qcom,rpmcc {
					compatible = "qcom,rpmcc-msm8916\0qcom,rpmcc";
					#clock-cells = <0x01>;
					phandle = <0x80>;
				};

				pm8916-regulators {
					compatible = "qcom,rpm-pm8916-regulators";
					phandle = <0x81>;

					s1 {
						phandle = <0x82>;
					};

					s3 {
						phandle = <0x83>;
					};

					s4 {
						phandle = <0x24>;
					};

					l1 {
						phandle = <0x84>;
					};

					l2 {
						phandle = <0x85>;
					};

					l3 {
						phandle = <0x86>;
					};

					l4 {
						phandle = <0x87>;
					};

					l5 {
						phandle = <0x25>;
					};

					l6 {
						phandle = <0x88>;
					};

					l7 {
						phandle = <0x89>;
					};

					l8 {
						phandle = <0x8a>;
					};

					l9 {
						phandle = <0x8b>;
					};

					l10 {
						phandle = <0x8c>;
					};

					l11 {
						phandle = <0x8d>;
					};

					l12 {
						phandle = <0x8e>;
					};

					l13 {
						phandle = <0x26>;
					};

					l14 {
						phandle = <0x8f>;
					};

					l15 {
						phandle = <0x90>;
					};

					l16 {
						phandle = <0x91>;
					};

					l17 {
						phandle = <0x92>;
					};

					l18 {
						phandle = <0x93>;
					};
				};
			};
		};
	};

	hexagon-smp2p {
		compatible = "qcom,smp2p";
		qcom,smem = <0x1b3 0x1ac>;
		interrupts = <0x00 0x1b 0x01>;
		qcom,ipc = <0x2d 0x08 0x0e>;
		qcom,local-pid = <0x00>;
		qcom,remote-pid = <0x01>;

		master-kernel {
			qcom,entry-name = "master-kernel";
			#qcom,smem-state-cells = <0x01>;
			phandle = <0x94>;
		};

		slave-kernel {
			qcom,entry-name = "slave-kernel";
			interrupt-controller;
			#interrupt-cells = <0x02>;
			phandle = <0x95>;
		};
	};

	wcnss-smp2p {
		compatible = "qcom,smp2p";
		qcom,smem = <0x1c3 0x1af>;
		interrupts = <0x00 0x8f 0x01>;
		qcom,ipc = <0x2d 0x08 0x12>;
		qcom,local-pid = <0x00>;
		qcom,remote-pid = <0x04>;

		master-kernel {
			qcom,entry-name = "master-kernel";
			#qcom,smem-state-cells = <0x01>;
			phandle = <0x96>;
		};

		slave-kernel {
			qcom,entry-name = "slave-kernel";
			interrupt-controller;
			#interrupt-cells = <0x02>;
			phandle = <0x97>;
		};
	};

	smsm {
		compatible = "qcom,smsm";
		#address-cells = <0x01>;
		#size-cells = <0x00>;
		qcom,ipc-1 = <0x2d 0x08 0x0d>;
		qcom,ipc-3 = <0x2d 0x08 0x13>;

		apps@0 {
			reg = <0x00>;
			#qcom,smem-state-cells = <0x01>;
			phandle = <0x98>;
		};

		hexagon@1 {
			reg = <0x01>;
			interrupts = <0x00 0x1a 0x01>;
			interrupt-controller;
			#interrupt-cells = <0x02>;
			phandle = <0x99>;
		};

		wcnss@6 {
			reg = <0x06>;
			interrupts = <0x00 0x90 0x01>;
			interrupt-controller;
			#interrupt-cells = <0x02>;
			phandle = <0x9a>;
		};
	};

	__symbols__ {
		smem_mem = "/reserved-memory/smem_region@86300000";
		mba_mem = "/reserved-memory/mba@8ea00000";
		CPU0 = "/cpus/cpu@0";
		CPU1 = "/cpus/cpu@1";
		CPU2 = "/cpus/cpu@2";
		CPU3 = "/cpus/cpu@3";
		L2_0 = "/cpus/l2-cache";
		CPU_SPC = "/cpus/idle-states/spc";
		cpu_alert0 = "/thermal-zones/cpu-thermal0/trips/trip0";
		cpu_crit0 = "/thermal-zones/cpu-thermal0/trips/trip1";
		cpu_alert1 = "/thermal-zones/cpu-thermal1/trips/trip0";
		cpu_crit1 = "/thermal-zones/cpu-thermal1/trips/trip1";
		xo_board = "/clocks/xo_board";
		sleep_clk = "/clocks/sleep_clk";
		scm = "/firmware/scm";
		soc = "/soc";
		msmgpio = "/soc/pinctrl@1000000";
		blsp1_uart1_default = "/soc/pinctrl@1000000/blsp1_uart1_default";
		blsp1_uart1_sleep = "/soc/pinctrl@1000000/blsp1_uart1_sleep";
		blsp1_uart2_default = "/soc/pinctrl@1000000/blsp1_uart2_default";
		blsp1_uart2_sleep = "/soc/pinctrl@1000000/blsp1_uart2_sleep";
		spi1_default = "/soc/pinctrl@1000000/spi1_default";
		spi1_sleep = "/soc/pinctrl@1000000/spi1_sleep";
		spi2_default = "/soc/pinctrl@1000000/spi2_default";
		spi2_sleep = "/soc/pinctrl@1000000/spi2_sleep";
		spi3_default = "/soc/pinctrl@1000000/spi3_default";
		spi3_sleep = "/soc/pinctrl@1000000/spi3_sleep";
		spi4_default = "/soc/pinctrl@1000000/spi4_default";
		spi4_sleep = "/soc/pinctrl@1000000/spi4_sleep";
		spi5_default = "/soc/pinctrl@1000000/spi5_default";
		spi5_sleep = "/soc/pinctrl@1000000/spi5_sleep";
		spi6_default = "/soc/pinctrl@1000000/spi6_default";
		spi6_sleep = "/soc/pinctrl@1000000/spi6_sleep";
		i2c2_default = "/soc/pinctrl@1000000/i2c2_default";
		i2c2_sleep = "/soc/pinctrl@1000000/i2c2_sleep";
		i2c4_default = "/soc/pinctrl@1000000/i2c4_default";
		i2c4_sleep = "/soc/pinctrl@1000000/i2c4_sleep";
		i2c6_default = "/soc/pinctrl@1000000/i2c6_default";
		i2c6_sleep = "/soc/pinctrl@1000000/i2c6_sleep";
		sdc2_cd_on = "/soc/pinctrl@1000000/sdhc2_cd_pin/cd_on";
		sdc2_cd_off = "/soc/pinctrl@1000000/sdhc2_cd_pin/cd_off";
		sdc1_clk_on = "/soc/pinctrl@1000000/pmx_sdc1_clk/clk_on";
		sdc1_clk_off = "/soc/pinctrl@1000000/pmx_sdc1_clk/clk_off";
		sdc1_cmd_on = "/soc/pinctrl@1000000/pmx_sdc1_cmd/cmd_on";
		sdc1_cmd_off = "/soc/pinctrl@1000000/pmx_sdc1_cmd/cmd_off";
		sdc1_data_on = "/soc/pinctrl@1000000/pmx_sdc1_data/data_on";
		sdc1_data_off = "/soc/pinctrl@1000000/pmx_sdc1_data/data_off";
		sdc2_clk_on = "/soc/pinctrl@1000000/pmx_sdc2_clk/clk_on";
		sdc2_clk_off = "/soc/pinctrl@1000000/pmx_sdc2_clk/clk_off";
		sdc2_cmd_on = "/soc/pinctrl@1000000/pmx_sdc2_cmd/cmd_on";
		sdc2_cmd_off = "/soc/pinctrl@1000000/pmx_sdc2_cmd/cmd_off";
		sdc2_data_on = "/soc/pinctrl@1000000/pmx_sdc2_data/data_on";
		sdc2_data_off = "/soc/pinctrl@1000000/pmx_sdc2_data/data_off";
		ext_codec_lines_act = "/soc/pinctrl@1000000/ext-codec-lines/lines_on";
		ext_codec_lines_sus = "/soc/pinctrl@1000000/ext-codec-lines/lines_off";
		cdc_pdm_lines_act = "/soc/pinctrl@1000000/cdc-pdm-lines/pdm_lines_on";
		cdc_pdm_lines_sus = "/soc/pinctrl@1000000/cdc-pdm-lines/pdm_lines_off";
		ext_pri_tlmm_lines_act = "/soc/pinctrl@1000000/ext-pri-tlmm-lines/ext_pa_on";
		ext_pri_tlmm_lines_sus = "/soc/pinctrl@1000000/ext-pri-tlmm-lines/ext_pa_off";
		ext_pri_ws_act = "/soc/pinctrl@1000000/ext-pri-ws-line/ext_pa_on";
		ext_pri_ws_sus = "/soc/pinctrl@1000000/ext-pri-ws-line/ext_pa_off";
		ext_mclk_tlmm_lines_act = "/soc/pinctrl@1000000/ext-mclk-tlmm-lines/mclk_lines_on";
		ext_mclk_tlmm_lines_sus = "/soc/pinctrl@1000000/ext-mclk-tlmm-lines/mclk_lines_off";
		ext_sec_tlmm_lines_act = "/soc/pinctrl@1000000/ext-sec-tlmm-lines/tlmm_lines_on";
		ext_sec_tlmm_lines_sus = "/soc/pinctrl@1000000/ext-sec-tlmm-lines/tlmm_lines_off";
		cdc_dmic_lines_act = "/soc/pinctrl@1000000/cdc-dmic-lines/dmic_lines_on";
		cdc_dmic_lines_sus = "/soc/pinctrl@1000000/cdc-dmic-lines/dmic_lines_off";
		cross_conn_det_act = "/soc/pinctrl@1000000/cross-conn-det/lines_on";
		cross_conn_det_sus = "/soc/pinctrl@1000000/cross-conn-det/lines_off";
		gcc = "/soc/clock-controller@1800000";
		tcsr_mutex_regs = "/soc/syscon@1905000";
		tcsr = "/soc/syscon@1937000";
		tcsr_mutex = "/soc/hwlock";
		rpm_msg_ram = "/soc/memory@60000";
		blsp1_uart1 = "/soc/serial@78af000";
		apcs = "/soc/syscon@b011000";
		blsp1_uart2 = "/soc/serial@78b0000";
		blsp_dma = "/soc/dma@7884000";
		blsp_spi1 = "/soc/spi@78b5000";
		blsp_spi2 = "/soc/spi@78b6000";
		blsp_spi3 = "/soc/spi@78b7000";
		blsp_spi4 = "/soc/spi@78b8000";
		blsp_spi5 = "/soc/spi@78b9000";
		blsp_spi6 = "/soc/spi@78ba000";
		blsp_i2c2 = "/soc/i2c@78b6000";
		blsp_i2c4 = "/soc/i2c@78b8000";
		blsp_i2c6 = "/soc/i2c@78ba000";
		lpass = "/soc/lpass@07708000";
		sdhc_1 = "/soc/sdhci@07824000";
		sdhc_2 = "/soc/sdhci@07864000";
		usb_dev = "/soc/usb@78d9000";
		usb_host = "/soc/ehci@78d9000";
		usb_otg = "/soc/phy@78d9000";
		intc = "/soc/interrupt-controller@b000000";
		spmi_bus = "/soc/spmi@200f000";
		pm8916_0 = "/soc/spmi@200f000/pm8916@0";
		pm8916_revid = "/soc/spmi@200f000/pm8916@0/qcom,revid@100";
		pm8916_pon = "/soc/spmi@200f000/pm8916@0/qcom,power-on@800";
		pm8916_gpios = "/soc/spmi@200f000/pm8916@0/pinctrl@c000";
		pm8916_mpps = "/soc/spmi@200f000/pm8916@0/mpps@a000";
		pm8916_coincell = "/soc/spmi@200f000/pm8916@0/qcom,coincell@2800";
		pm8916_rtc = "/soc/spmi@200f000/pm8916@0/qcom,pm8916_rtc";
		pm8916_vadc = "/soc/spmi@200f000/pm8916@0/vadc@3100";
		pm8916_tz = "/soc/spmi@200f000/pm8916@0/qcom,temp-alarm@2400";
		pm8916_adc_tm = "/soc/spmi@200f000/pm8916@0/vadc@3400";
		pm8916_chg = "/soc/spmi@200f000/pm8916@0/qcom,charger";
		pm8916_bms = "/soc/spmi@200f000/pm8916@0/qcom,vmbms";
		pm8916_leds = "/soc/spmi@200f000/pm8916@0/qcom,leds@a100";
		pm8916_1 = "/soc/spmi@200f000/pm8916@1";
		pm8916_pwm = "/soc/spmi@200f000/pm8916@1/qcom,pwms@bc00";
		pm8916_vib = "/soc/spmi@200f000/pm8916@1/qcom,vibrator@c000";
		pm8916_tombak_dig = "/soc/spmi@200f000/pm8916@1/msm8x16_wcd_codec@f000";
		pm8916_tombak_analog = "/soc/spmi@200f000/pm8916@1/msm8x16_wcd_codec@f100";
		qfprom = "/soc/qfprom@5c000";
		tsens_caldata = "/soc/qfprom@5c000/caldata@d0";
		tsens_calsel = "/soc/qfprom@5c000/calsel@ec";
		tsens = "/soc/thermal-sensor@4a8000";
		mdss = "/soc/mdss@1a00000";
		mdp = "/soc/mdss@1a00000/mdp@1a01000";
		mdp5_intf1_out = "/soc/mdss@1a00000/mdp@1a01000/ports/port@0/endpoint";
		dsi0 = "/soc/mdss@1a00000/dsi@1a98000";
		dsi0_in = "/soc/mdss@1a00000/dsi@1a98000/ports/port@0/endpoint";
		dsi0_out = "/soc/mdss@1a00000/dsi@1a98000/ports/port@1/endpoint";
		dsi_phy0 = "/soc/mdss@1a00000/dsi-phy@1a98300";
		rpmcc = "/smd/rpm/rpm_requests/qcom,rpmcc";
		smd_rpm_regulators = "/smd/rpm/rpm_requests/pm8916-regulators";
		pm8916_s1 = "/smd/rpm/rpm_requests/pm8916-regulators/s1";
		pm8916_s3 = "/smd/rpm/rpm_requests/pm8916-regulators/s3";
		pm8916_s4 = "/smd/rpm/rpm_requests/pm8916-regulators/s4";
		pm8916_l1 = "/smd/rpm/rpm_requests/pm8916-regulators/l1";
		pm8916_l2 = "/smd/rpm/rpm_requests/pm8916-regulators/l2";
		pm8916_l3 = "/smd/rpm/rpm_requests/pm8916-regulators/l3";
		pm8916_l4 = "/smd/rpm/rpm_requests/pm8916-regulators/l4";
		pm8916_l5 = "/smd/rpm/rpm_requests/pm8916-regulators/l5";
		pm8916_l6 = "/smd/rpm/rpm_requests/pm8916-regulators/l6";
		pm8916_l7 = "/smd/rpm/rpm_requests/pm8916-regulators/l7";
		pm8916_l8 = "/smd/rpm/rpm_requests/pm8916-regulators/l8";
		pm8916_l9 = "/smd/rpm/rpm_requests/pm8916-regulators/l9";
		pm8916_l10 = "/smd/rpm/rpm_requests/pm8916-regulators/l10";
		pm8916_l11 = "/smd/rpm/rpm_requests/pm8916-regulators/l11";
		pm8916_l12 = "/smd/rpm/rpm_requests/pm8916-regulators/l12";
		pm8916_l13 = "/smd/rpm/rpm_requests/pm8916-regulators/l13";
		pm8916_l14 = "/smd/rpm/rpm_requests/pm8916-regulators/l14";
		pm8916_l15 = "/smd/rpm/rpm_requests/pm8916-regulators/l15";
		pm8916_l16 = "/smd/rpm/rpm_requests/pm8916-regulators/l16";
		pm8916_l17 = "/smd/rpm/rpm_requests/pm8916-regulators/l17";
		pm8916_l18 = "/smd/rpm/rpm_requests/pm8916-regulators/l18";
		hexagon_smp2p_out = "/hexagon-smp2p/master-kernel";
		hexagon_smp2p_in = "/hexagon-smp2p/slave-kernel";
		wcnss_smp2p_out = "/wcnss-smp2p/master-kernel";
		wcnss_smp2p_in = "/wcnss-smp2p/slave-kernel";
		apps_smsm = "/smsm/apps@0";
		hexagon_smsm = "/smsm/hexagon@1";
		wcnss_smsm = "/smsm/wcnss@6";
	};
};
